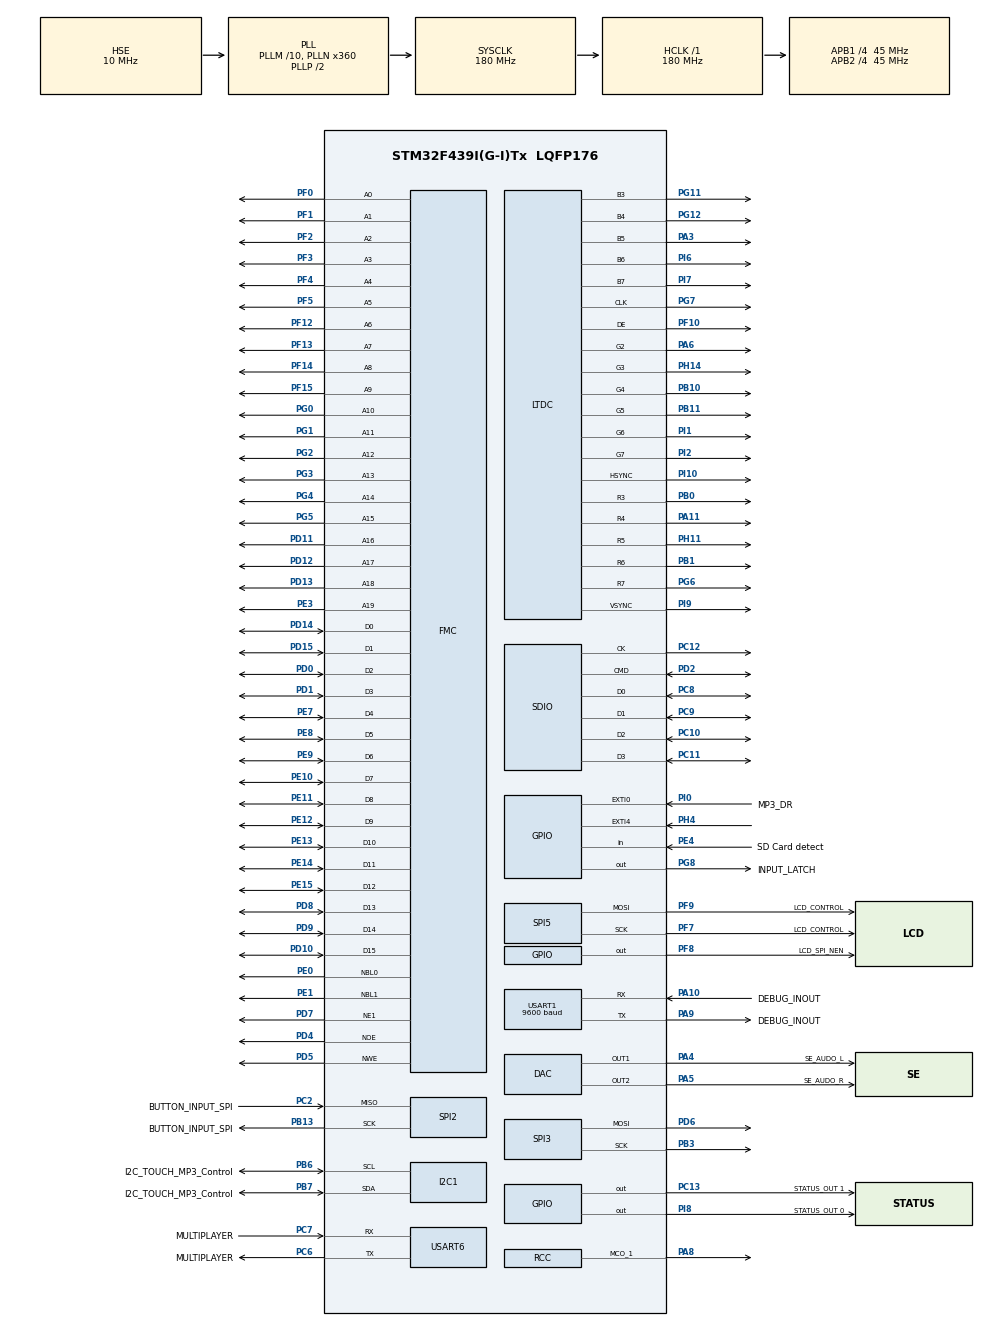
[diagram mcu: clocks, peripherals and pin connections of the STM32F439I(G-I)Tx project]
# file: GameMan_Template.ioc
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FATFS._USE_LFN=3
FATFS._USE_MKFS=1
FMC.AddressSetupTime1=0
FMC.BusTurnAroundDuration1=0
FMC.DataSetupTime1=2
FMC.WriteOperation1=FMC_WRITE_OPERATION_ENABLE
I2C1.NoStretchMode=I2C_NOSTRETCH_DISABLED
LTDC.ActiveH-RGB565=240
LTDC.ActiveW-RGB565=320
LTDC.DEPolarity-RGB565=LTDC_DEPOLARITY_AL
LTDC.HBP-RGB565=70
LTDC.HFP-RGB565=18
LTDC.HSync-RGB565=1
LTDC.VBP-RGB565=13
LTDC.VFP-RGB565=10
LTDC.VSync-RGB565=1
Mcu.Family=STM32F4
Mcu.Name=STM32F439I(G-I)Tx
Mcu.Package=LQFP176
NVIC.PriorityGroup=NVIC_PRIORITYGROUP_4
PA10.GPIO_Label=DEBUG_INOUT
PA10.GPIO_Mode=GPIO_MODE_AF_PP
PA10.GPIO_PuPd=GPIO_PULLUP
PA10.GPIO_Speed=GPIO_SPEED_MEDIUM
PA10.Mode=Asynchronous
PA10.Signal=USART1_RX
PA11.GPIO_Mode=GPIO_MODE_AF_PP
PA11.GPIO_PuPd=GPIO_NOPULL
PA11.GPIO_Speed=GPIO_SPEED_MEDIUM
PA11.Mode=RGB565
PA11.Signal=LTDC_R4
PA13.Mode=Serial-Wire
PA13.Signal=SYS_JTMS-SWDIO
PA14.Mode=Serial-Wire
PA14.Signal=SYS_JTCK-SWCLK
PA3.GPIO_Mode=GPIO_MODE_AF_PP
PA3.GPIO_PuPd=GPIO_NOPULL
PA3.GPIO_Speed=GPIO_SPEED_MEDIUM
PA3.Mode=RGB565
PA3.Signal=LTDC_B5
PA4.GPIO_Label=SE_AUDO_L
PA4.GPIO_Mode=GPIO_MODE_ANALOG
PA4.GPIO_PuPd=GPIO_NOPULL
PA4.Signal=COMP_DAC1_group
PA5.GPIO_Label=SE_AUDO_R
PA5.GPIO_Mode=GPIO_MODE_ANALOG
PA5.GPIO_PuPd=GPIO_NOPULL
PA5.Signal=COMP_DAC2_group
PA6.GPIO_Mode=GPIO_MODE_AF_PP
PA6.GPIO_PuPd=GPIO_NOPULL
PA6.GPIO_Speed=GPIO_SPEED_MEDIUM
PA6.Mode=RGB565
PA6.Signal=LTDC_G2
PA8.Mode=Clock-out-1
PA8.Signal=RCC_MCO_1
PA9.GPIO_Label=DEBUG_INOUT
PA9.GPIO_Mode=GPIO_MODE_AF_PP
PA9.GPIO_PuPd=GPIO_PULLUP
PA9.GPIO_Speed=GPIO_SPEED_MEDIUM
PA9.Mode=Asynchronous
PA9.Signal=USART1_TX
PB0.GPIO_Mode=GPIO_MODE_AF_PP
PB0.GPIO_PuPd=GPIO_NOPULL
PB0.GPIO_Speed=GPIO_SPEED_MEDIUM
PB0.Mode=RGB565
PB0.Signal=LTDC_R3
PB1.GPIO_Mode=GPIO_MODE_AF_PP
PB1.GPIO_PuPd=GPIO_NOPULL
PB1.GPIO_Speed=GPIO_SPEED_MEDIUM
PB1.Mode=RGB565
PB1.Signal=LTDC_R6
PB10.GPIO_Mode=GPIO_MODE_AF_PP
PB10.GPIO_PuPd=GPIO_NOPULL
PB10.GPIO_Speed=GPIO_SPEED_MEDIUM
PB10.Mode=RGB565
PB10.Signal=LTDC_G4
PB11.GPIO_Mode=GPIO_MODE_AF_PP
PB11.GPIO_PuPd=GPIO_NOPULL
PB11.GPIO_Speed=GPIO_SPEED_MEDIUM
PB11.Mode=RGB565
PB11.Signal=LTDC_G5
PB13.GPIO_Label=BUTTON_INPUT_SPI
PB13.GPIO_Mode=GPIO_MODE_AF_PP
PB13.GPIO_PuPd=GPIO_NOPULL
PB13.GPIO_Speed=GPIO_SPEED_FAST
PB13.Mode=RX_Only_Simplex_Unidirect_Master
PB13.Signal=SPI2_SCK
PB3.GPIO_Mode=GPIO_MODE_AF_PP
PB3.GPIO_PuPd=GPIO_NOPULL
PB3.GPIO_Speed=GPIO_SPEED_FAST
PB3.Mode=TX_Only_Simplex_Unidirect_Master
PB3.Signal=SPI3_SCK
PB6.GPIO_Label=I2C_TOUCH_MP3_Control
PB6.GPIO_Mode=GPIO_MODE_AF_OD
PB6.GPIO_PuPdOD=GPIO_PULLUP
PB6.GPIO_Speed=GPIO_SPEED_LOW
PB6.Mode=I2C
PB6.Signal=I2C1_SCL
PB7.GPIO_Label=I2C_TOUCH_MP3_Control
PB7.GPIO_Mode=GPIO_MODE_AF_OD
PB7.GPIO_PuPdOD=GPIO_PULLUP
PB7.GPIO_Speed=GPIO_SPEED_LOW
PB7.Mode=I2C
PB7.Signal=I2C1_SDA
PC10.GPIO_Mode=GPIO_MODE_AF_PP
PC10.GPIO_PuPd=GPIO_NOPULL
PC10.GPIO_Speed=GPIO_SPEED_HIGH
PC10.Mode=SD_4_bits_Wide_bus
PC10.Signal=SDIO_D2
PC11.GPIO_Mode=GPIO_MODE_AF_PP
PC11.GPIO_PuPd=GPIO_NOPULL
PC11.GPIO_Speed=GPIO_SPEED_HIGH
PC11.Mode=SD_4_bits_Wide_bus
PC11.Signal=SDIO_D3
PC12.GPIO_Mode=GPIO_MODE_AF_PP
PC12.GPIO_PuPd=GPIO_NOPULL
PC12.GPIO_Speed=GPIO_SPEED_HIGH
PC12.Mode=SD_4_bits_Wide_bus
PC12.Signal=SDIO_CK
PC13.GPIO_Label=STATUS_OUT 1
PC13.GPIO_ModeDefaultOutputPP=GPIO_MODE_OUTPUT_PP
PC13.GPIO_PuPd=GPIO_NOPULL
PC13.GPIO_Speed=GPIO_SPEED_LOW
PC13.Signal=GPIO_Output
PC14/OSC32_IN.Mode=LSE-External-Oscillator
PC14/OSC32_IN.Signal=RCC_OSC32_IN
PC15/OSC32_OUT.Mode=LSE-External-Oscillator
PC15/OSC32_OUT.Signal=RCC_OSC32_OUT
PC2.GPIO_Label=BUTTON_INPUT_SPI
PC2.GPIO_Mode=GPIO_MODE_AF_PP
PC2.GPIO_PuPd=GPIO_NOPULL
PC2.GPIO_Speed=GPIO_SPEED_FAST
PC2.Mode=RX_Only_Simplex_Unidirect_Master
PC2.Signal=SPI2_MISO
PC6.GPIO_Label=MULTIPLAYER
PC6.GPIO_Mode=GPIO_MODE_AF_PP
PC6.GPIO_PuPd=GPIO_PULLUP
PC6.GPIO_Speed=GPIO_SPEED_LOW
PC6.Mode=Asynchronous
PC6.Signal=USART6_TX
PC7.GPIO_Label=MULTIPLAYER
PC7.GPIO_Mode=GPIO_MODE_AF_PP
PC7.GPIO_PuPd=GPIO_PULLUP
PC7.GPIO_Speed=GPIO_SPEED_LOW
PC7.Mode=Asynchronous
PC7.Signal=USART6_RX
PC8.GPIO_Mode=GPIO_MODE_AF_PP
PC8.GPIO_PuPd=GPIO_NOPULL
PC8.GPIO_Speed=GPIO_SPEED_HIGH
PC8.Mode=SD_4_bits_Wide_bus
PC8.Signal=SDIO_D0
PC9.GPIO_Mode=GPIO_MODE_AF_PP
PC9.GPIO_PuPd=GPIO_NOPULL
PC9.GPIO_Speed=GPIO_SPEED_HIGH
PC9.Mode=SD_4_bits_Wide_bus
PC9.Signal=SDIO_D1
PD0.GPIO_Mode=GPIO_MODE_AF_PP
PD0.GPIO_PuPd=GPIO_NOPULL
PD0.GPIO_Speed=GPIO_SPEED_HIGH
PD0.Signal=FMC_D2_DA2
PD1.GPIO_Mode=GPIO_MODE_AF_PP
PD1.GPIO_PuPd=GPIO_NOPULL
PD1.GPIO_Speed=GPIO_SPEED_HIGH
PD1.Signal=FMC_D3_DA3
PD10.GPIO_Mode=GPIO_MODE_AF_PP
PD10.GPIO_PuPd=GPIO_NOPULL
PD10.GPIO_Speed=GPIO_SPEED_HIGH
PD10.Signal=FMC_D15_DA15
PD11.GPIO_Mode=GPIO_MODE_AF_PP
PD11.GPIO_PuPd=GPIO_NOPULL
PD11.GPIO_Speed=GPIO_SPEED_HIGH
PD11.Signal=FMC_A16_CLE
PD12.GPIO_Mode=GPIO_MODE_AF_PP
PD12.GPIO_PuPd=GPIO_NOPULL
PD12.GPIO_Speed=GPIO_SPEED_HIGH
PD12.Signal=FMC_A17_ALE
PD13.GPIO_Mode=GPIO_MODE_AF_PP
PD13.GPIO_PuPd=GPIO_NOPULL
PD13.GPIO_Speed=GPIO_SPEED_HIGH
PD13.Signal=FMC_A18
PD14.GPIO_Mode=GPIO_MODE_AF_PP
PD14.GPIO_PuPd=GPIO_NOPULL
PD14.GPIO_Speed=GPIO_SPEED_HIGH
PD14.Signal=FMC_D0_DA0
PD15.GPIO_Mode=GPIO_MODE_AF_PP
PD15.GPIO_PuPd=GPIO_NOPULL
PD15.GPIO_Speed=GPIO_SPEED_HIGH
PD15.Signal=FMC_D1_DA1
PD2.GPIO_Mode=GPIO_MODE_AF_PP
PD2.GPIO_PuPd=GPIO_NOPULL
PD2.GPIO_Speed=GPIO_SPEED_HIGH
PD2.Mode=SD_4_bits_Wide_bus
PD2.Signal=SDIO_CMD
PD4.GPIO_Mode=GPIO_MODE_AF_PP
PD4.GPIO_PuPd=GPIO_NOPULL
PD4.GPIO_Speed=GPIO_SPEED_HIGH
PD4.Signal=FMC_NOE
PD5.GPIO_Mode=GPIO_MODE_AF_PP
PD5.GPIO_PuPd=GPIO_NOPULL
PD5.GPIO_Speed=GPIO_SPEED_HIGH
PD5.Signal=FMC_NWE
PD6.GPIO_Mode=GPIO_MODE_AF_PP
PD6.GPIO_PuPd=GPIO_NOPULL
PD6.GPIO_Speed=GPIO_SPEED_FAST
PD6.Mode=TX_Only_Simplex_Unidirect_Master
PD6.Signal=SPI3_MOSI
PD7.GPIO_Mode=GPIO_MODE_AF_PP
PD7.GPIO_PuPd=GPIO_NOPULL
PD7.GPIO_Speed=GPIO_SPEED_HIGH
PD7.Mode=NorPsramChipSelect1_1
PD7.Signal=FMC_NE1
PD8.GPIO_Mode=GPIO_MODE_AF_PP
PD8.GPIO_PuPd=GPIO_NOPULL
PD8.GPIO_Speed=GPIO_SPEED_HIGH
PD8.Signal=FMC_D13_DA13
PD9.GPIO_Mode=GPIO_MODE_AF_PP
PD9.GPIO_PuPd=GPIO_NOPULL
PD9.GPIO_Speed=GPIO_SPEED_HIGH
PD9.Signal=FMC_D14_DA14
PE0.GPIO_Mode=GPIO_MODE_AF_PP
PE0.GPIO_PuPd=GPIO_NOPULL
PE0.GPIO_Speed=GPIO_SPEED_HIGH
PE0.Signal=FMC_NBL0
PE1.GPIO_Mode=GPIO_MODE_AF_PP
PE1.GPIO_PuPd=GPIO_NOPULL
PE1.GPIO_Speed=GPIO_SPEED_HIGH
PE1.Signal=FMC_NBL1
PE10.GPIO_Mode=GPIO_MODE_AF_PP
PE10.GPIO_PuPd=GPIO_NOPULL
PE10.GPIO_Speed=GPIO_SPEED_HIGH
PE10.Signal=FMC_D7_DA7
PE11.GPIO_Mode=GPIO_MODE_AF_PP
PE11.GPIO_PuPd=GPIO_NOPULL
PE11.GPIO_Speed=GPIO_SPEED_HIGH
PE11.Signal=FMC_D8_DA8
PE12.GPIO_Mode=GPIO_MODE_AF_PP
PE12.GPIO_PuPd=GPIO_NOPULL
PE12.GPIO_Speed=GPIO_SPEED_HIGH
PE12.Signal=FMC_D9_DA9
PE13.GPIO_Mode=GPIO_MODE_AF_PP
PE13.GPIO_PuPd=GPIO_NOPULL
PE13.GPIO_Speed=GPIO_SPEED_HIGH
PE13.Signal=FMC_D10_DA10
PE14.GPIO_Mode=GPIO_MODE_AF_PP
PE14.GPIO_PuPd=GPIO_NOPULL
PE14.GPIO_Speed=GPIO_SPEED_HIGH
PE14.Signal=FMC_D11_DA11
PE15.GPIO_Mode=GPIO_MODE_AF_PP
PE15.GPIO_PuPd=GPIO_NOPULL
PE15.GPIO_Speed=GPIO_SPEED_HIGH
PE15.Signal=FMC_D12_DA12
PE3.GPIO_Mode=GPIO_MODE_AF_PP
PE3.GPIO_PuPd=GPIO_NOPULL
PE3.GPIO_Speed=GPIO_SPEED_HIGH
PE3.Signal=FMC_A19
PE4.GPIO_Label=SD Card detect
PE4.GPIO_Mode=GPIO_MODE_INPUT
PE4.GPIO_PuPd=GPIO_NOPULL
PE4.Signal=GPIO_Input
PE7.GPIO_Mode=GPIO_MODE_AF_PP
PE7.GPIO_PuPd=GPIO_NOPULL
PE7.GPIO_Speed=GPIO_SPEED_HIGH
PE7.Signal=FMC_D4_DA4
PE8.GPIO_Mode=GPIO_MODE_AF_PP
PE8.GPIO_PuPd=GPIO_NOPULL
PE8.GPIO_Speed=GPIO_SPEED_HIGH
PE8.Signal=FMC_D5_DA5
PE9.GPIO_Mode=GPIO_MODE_AF_PP
PE9.GPIO_PuPd=GPIO_NOPULL
PE9.GPIO_Speed=GPIO_SPEED_HIGH
PE9.Signal=FMC_D6_DA6
PF0.GPIO_Mode=GPIO_MODE_AF_PP
PF0.GPIO_PuPd=GPIO_NOPULL
PF0.GPIO_Speed=GPIO_SPEED_HIGH
PF0.Signal=FMC_A0
PF1.GPIO_Mode=GPIO_MODE_AF_PP
PF1.GPIO_PuPd=GPIO_NOPULL
PF1.GPIO_Speed=GPIO_SPEED_HIGH
PF1.Signal=FMC_A1
PF10.GPIO_Mode=GPIO_MODE_AF_PP
PF10.GPIO_PuPd=GPIO_NOPULL
PF10.GPIO_Speed=GPIO_SPEED_MEDIUM
PF10.Mode=RGB565
PF10.Signal=LTDC_DE
PF12.GPIO_Mode=GPIO_MODE_AF_PP
PF12.GPIO_PuPd=GPIO_NOPULL
PF12.GPIO_Speed=GPIO_SPEED_HIGH
PF12.Signal=FMC_A6
PF13.GPIO_Mode=GPIO_MODE_AF_PP
PF13.GPIO_PuPd=GPIO_NOPULL
PF13.GPIO_Speed=GPIO_SPEED_HIGH
PF13.Signal=FMC_A7
PF14.GPIO_Mode=GPIO_MODE_AF_PP
PF14.GPIO_PuPd=GPIO_NOPULL
PF14.GPIO_Speed=GPIO_SPEED_HIGH
PF14.Signal=FMC_A8
PF15.GPIO_Mode=GPIO_MODE_AF_PP
PF15.GPIO_PuPd=GPIO_NOPULL
PF15.GPIO_Speed=GPIO_SPEED_HIGH
PF15.Signal=FMC_A9
PF2.GPIO_Mode=GPIO_MODE_AF_PP
PF2.GPIO_PuPd=GPIO_NOPULL
PF2.GPIO_Speed=GPIO_SPEED_HIGH
PF2.Signal=FMC_A2
PF3.GPIO_Mode=GPIO_MODE_AF_PP
PF3.GPIO_PuPd=GPIO_NOPULL
PF3.GPIO_Speed=GPIO_SPEED_HIGH
PF3.Signal=FMC_A3
PF4.GPIO_Mode=GPIO_MODE_AF_PP
PF4.GPIO_PuPd=GPIO_NOPULL
PF4.GPIO_Speed=GPIO_SPEED_HIGH
PF4.Signal=FMC_A4
PF5.GPIO_Mode=GPIO_MODE_AF_PP
PF5.GPIO_PuPd=GPIO_NOPULL
PF5.GPIO_Speed=GPIO_SPEED_HIGH
PF5.Signal=FMC_A5
PF7.GPIO_Label=LCD_CONTROL
PF7.GPIO_Mode=GPIO_MODE_AF_PP
PF7.GPIO_PuPd=GPIO_NOPULL
PF7.GPIO_Speed=GPIO_SPEED_FAST
PF7.Mode=TX_Only_Simplex_Unidirect_Master
PF7.Signal=SPI5_SCK
PF8.GPIO_Label=LCD_SPI_NEN
PF8.GPIO_ModeDefaultOutputPP=GPIO_MODE_OUTPUT_PP
PF8.GPIO_PuPd=GPIO_NOPULL
PF8.GPIO_Speed=GPIO_SPEED_LOW
PF8.Signal=GPIO_Output
PF9.GPIO_Label=LCD_CONTROL
PF9.GPIO_Mode=GPIO_MODE_AF_PP
PF9.GPIO_PuPd=GPIO_NOPULL
PF9.GPIO_Speed=GPIO_SPEED_FAST
PF9.Mode=TX_Only_Simplex_Unidirect_Master
PF9.Signal=SPI5_MOSI
PG0.GPIO_Mode=GPIO_MODE_AF_PP
PG0.GPIO_PuPd=GPIO_NOPULL
PG0.GPIO_Speed=GPIO_SPEED_HIGH
PG0.Signal=FMC_A10
PG1.GPIO_Mode=GPIO_MODE_AF_PP
PG1.GPIO_PuPd=GPIO_NOPULL
PG1.GPIO_Speed=GPIO_SPEED_HIGH
PG1.Signal=FMC_A11
PG11.GPIO_Mode=GPIO_MODE_AF_PP
PG11.GPIO_PuPd=GPIO_NOPULL
PG11.GPIO_Speed=GPIO_SPEED_MEDIUM
PG11.Mode=RGB565
PG11.Signal=LTDC_B3
PG12.GPIO_Mode=GPIO_MODE_AF_PP
PG12.GPIO_PuPd=GPIO_NOPULL
PG12.GPIO_Speed=GPIO_SPEED_MEDIUM
PG12.Mode=RGB565
PG12.Signal=LTDC_B4
PG2.GPIO_Mode=GPIO_MODE_AF_PP
PG2.GPIO_PuPd=GPIO_NOPULL
PG2.GPIO_Speed=GPIO_SPEED_HIGH
PG2.Signal=FMC_A12
PG3.GPIO_Mode=GPIO_MODE_AF_PP
PG3.GPIO_PuPd=GPIO_NOPULL
PG3.GPIO_Speed=GPIO_SPEED_HIGH
PG3.Signal=FMC_A13
PG4.GPIO_Mode=GPIO_MODE_AF_PP
PG4.GPIO_PuPd=GPIO_NOPULL
PG4.GPIO_Speed=GPIO_SPEED_HIGH
PG4.Signal=FMC_A14_BA0
PG5.GPIO_Mode=GPIO_MODE_AF_PP
PG5.GPIO_PuPd=GPIO_NOPULL
PG5.GPIO_Speed=GPIO_SPEED_HIGH
PG5.Signal=FMC_A15_BA1
PG6.GPIO_Mode=GPIO_MODE_AF_PP
PG6.GPIO_PuPd=GPIO_NOPULL
PG6.GPIO_Speed=GPIO_SPEED_MEDIUM
PG6.Mode=RGB565
PG6.Signal=LTDC_R7
PG7.GPIO_Mode=GPIO_MODE_AF_PP
PG7.GPIO_PuPd=GPIO_NOPULL
PG7.GPIO_Speed=GPIO_SPEED_MEDIUM
PG7.Mode=RGB565
PG7.Signal=LTDC_CLK
PG8.GPIO_Label=INPUT_LATCH
PG8.GPIO_ModeDefaultOutputPP=GPIO_MODE_OUTPUT_PP
PG8.GPIO_PuPd=GPIO_NOPULL
PG8.GPIO_Speed=GPIO_SPEED_LOW
PG8.Signal=GPIO_Output
PH0/OSC_IN.Mode=HSE-External-Oscillator
PH0/OSC_IN.Signal=RCC_OSC_IN
PH1/OSC_OUT.Mode=HSE-External-Oscillator
PH1/OSC_OUT.Signal=RCC_OSC_OUT
PH11.GPIO_Mode=GPIO_MODE_AF_PP
PH11.GPIO_PuPd=GPIO_NOPULL
PH11.GPIO_Speed=GPIO_SPEED_MEDIUM
PH11.Mode=RGB565
PH11.Signal=LTDC_R5
PH14.GPIO_Mode=GPIO_MODE_AF_PP
PH14.GPIO_PuPd=GPIO_NOPULL
PH14.GPIO_Speed=GPIO_SPEED_MEDIUM
PH14.Mode=RGB565
PH14.Signal=LTDC_G3
PH4.Signal=GPXTI4
PI0.GPIO_Label=MP3_DR
PI0.GPIO_ModeDefaultEXTI=GPIO_MODE_EVT_RISING
PI0.GPIO_PuPd=GPIO_NOPULL
PI0.Signal=GPXTI0
PI1.GPIO_Mode=GPIO_MODE_AF_PP
PI1.GPIO_PuPd=GPIO_NOPULL
PI1.GPIO_Speed=GPIO_SPEED_MEDIUM
PI1.Mode=RGB565
PI1.Signal=LTDC_G6
PI10.GPIO_Mode=GPIO_MODE_AF_PP
PI10.GPIO_PuPd=GPIO_NOPULL
PI10.GPIO_Speed=GPIO_SPEED_MEDIUM
PI10.Mode=RGB565
PI10.Signal=LTDC_HSYNC
PI2.GPIO_Mode=GPIO_MODE_AF_PP
PI2.GPIO_PuPd=GPIO_NOPULL
PI2.GPIO_Speed=GPIO_SPEED_MEDIUM
PI2.Mode=RGB565
PI2.Signal=LTDC_G7
PI6.GPIO_Mode=GPIO_MODE_AF_PP
PI6.GPIO_PuPd=GPIO_NOPULL
PI6.GPIO_Speed=GPIO_SPEED_MEDIUM
PI6.Mode=RGB565
PI6.Signal=LTDC_B6
PI7.GPIO_Mode=GPIO_MODE_AF_PP
PI7.GPIO_PuPd=GPIO_NOPULL
PI7.GPIO_Speed=GPIO_SPEED_MEDIUM
PI7.Mode=RGB565
PI7.Signal=LTDC_B7
PI8.GPIO_Label=STATUS_OUT 0
PI8.GPIO_ModeDefaultOutputPP=GPIO_MODE_OUTPUT_PP
PI8.GPIO_PuPd=GPIO_NOPULL
PI8.GPIO_Speed=GPIO_SPEED_LOW
PI8.Signal=GPIO_Output
PI9.GPIO_Mode=GPIO_MODE_AF_PP
PI9.GPIO_PuPd=GPIO_NOPULL
PI9.GPIO_Speed=GPIO_SPEED_MEDIUM
PI9.Mode=RGB565
PI9.Signal=LTDC_VSYNC
ProjectManager.TargetToolchain=MDK-ARM 4.73
RCC.48MHZClocksFreq_Value=45000000
RCC.AHBFreq_Value=180000000
RCC.APB1CLKDivider=RCC_HCLK_DIV4
RCC.APB1Freq_Value=45000000
RCC.APB1TimFreq_Value=90000000
RCC.APB2CLKDivider=RCC_HCLK_DIV4
RCC.APB2Freq_Value=45000000
RCC.APB2TimFreq_Value=90000000
RCC.CortexFreq_Value=22500000
RCC.HCLKFreq_Value=180000000
RCC.HSE_VALUE=10000000
RCC.HSI_VALUE=16000000
RCC.LSE_VALUE=32768
RCC.PLLM=10
RCC.PLLN=360
RCC.PLLQ=8
RCC.PLLSAIDivR=RCC_PLLSAIDIVR_8
RCC.PLLSAIN=256
RCC.PLLSAIR=5
RCC.PLLSourceVirtual=RCC_PLLSOURCE_HSE
RCC.SYSCLKFreq_VALUE=180000000
RCC.SYSCLKSource=RCC_SYSCLKSOURCE_PLLCLK
RCC.VCOOutputFreq_Value=360000000
SDIO.BusWide-SD_4_bits_Wide_bus=SDIO_BUS_WIDE_4B
SH.COMP_DAC1_group.0=DAC_OUT1,DAC_OUT1
SH.COMP_DAC2_group.0=DAC_OUT2,DAC_OUT2
SH.FMC_A0.0=FMC_A0,20b-a1
SH.FMC_A1.0=FMC_A1,20b-a1
SH.FMC_A10.0=FMC_A10,20b-a1
SH.FMC_A11.0=FMC_A11,20b-a1
SH.FMC_A12.0=FMC_A12,20b-a1
SH.FMC_A13.0=FMC_A13,20b-a1
SH.FMC_A14_BA0.0=FMC_A14,20b-a1
SH.FMC_A15_BA1.0=FMC_A15,20b-a1
SH.FMC_A16_CLE.0=FMC_A16,20b-a1
SH.FMC_A17_ALE.0=FMC_A17,20b-a1
SH.FMC_A18.0=FMC_A18,20b-a1
SH.FMC_A19.0=FMC_A19,20b-a1
SH.FMC_A2.0=FMC_A2,20b-a1
SH.FMC_A3.0=FMC_A3,20b-a1
SH.FMC_A4.0=FMC_A4,20b-a1
SH.FMC_A5.0=FMC_A5,20b-a1
SH.FMC_A6.0=FMC_A6,20b-a1
SH.FMC_A7.0=FMC_A7,20b-a1
SH.FMC_A8.0=FMC_A8,20b-a1
SH.FMC_A9.0=FMC_A9,20b-a1
SH.FMC_D0_DA0.0=FMC_D0,16b-d1
SH.FMC_D10_DA10.0=FMC_D10,16b-d1
SH.FMC_D11_DA11.0=FMC_D11,16b-d1
SH.FMC_D12_DA12.0=FMC_D12,16b-d1
SH.FMC_D13_DA13.0=FMC_D13,16b-d1
SH.FMC_D14_DA14.0=FMC_D14,16b-d1
SH.FMC_D15_DA15.0=FMC_D15,16b-d1
SH.FMC_D1_DA1.0=FMC_D1,16b-d1
SH.FMC_D2_DA2.0=FMC_D2,16b-d1
SH.FMC_D3_DA3.0=FMC_D3,16b-d1
SH.FMC_D4_DA4.0=FMC_D4,16b-d1
SH.FMC_D5_DA5.0=FMC_D5,16b-d1
SH.FMC_D6_DA6.0=FMC_D6,16b-d1
SH.FMC_D7_DA7.0=FMC_D7,16b-d1
SH.FMC_D8_DA8.0=FMC_D8,16b-d1
SH.FMC_D9_DA9.0=FMC_D9,16b-d1
SH.FMC_NBL0.0=FMC_NBL0,2ByteEnable1
SH.FMC_NBL1.0=FMC_NBL1,2ByteEnable1
SH.FMC_NOE.0=FMC_NOE,Sram1
SH.FMC_NWE.0=FMC_NWE,Sram1
SPI2.CalculateBaudRate-RX_Only_Simplex_Unidirect_Master=22.5 MBits/s
SPI2.DataSize-RX_Only_Simplex_Unidirect_Master=SPI_DATASIZE_16BIT
SPI2.Direction-RX_Only_Simplex_Unidirect_Master=SPI_DIRECTION_2LINES_RXONLY
SPI2.Mode-RX_Only_Simplex_Unidirect_Master=SPI_MODE_MASTER
SPI3.BaudRatePrescaler-TX_Only_Simplex_Unidirect_Master=SPI_BAUDRATEPRESCALER_4
SPI3.CLKPolarity-TX_Only_Simplex_Unidirect_Master=SPI_POLARITY_HIGH
SPI3.CalculateBaudRate-TX_Only_Simplex_Unidirect_Master=11.25 MBits/s
SPI3.Mode-TX_Only_Simplex_Unidirect_Master=SPI_MODE_MASTER
SPI5.BaudRatePrescaler-TX_Only_Simplex_Unidirect_Master=SPI_BAUDRATEPRESCALER_16
SPI5.CalculateBaudRate-TX_Only_Simplex_Unidirect_Master=2.8125 MBits/s
SPI5.Mode-TX_Only_Simplex_Unidirect_Master=SPI_MODE_MASTER
USART1.BaudRate=9600
VP_DMA2D_VS_DMA2D.Mode=DMA2D_Activate
VP_FATFS_VS_SDIO.Mode=SDIO
VP_RNG_VS_RNG.Mode=RNG_Activate

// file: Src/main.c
/**
  ******************************************************************************
  * File Name          : main.c
  * Date               : 02/03/2015 17:16:37
  * Description        : Main program body
  ******************************************************************************
  *
  * COPYRIGHT(c) 2015 STMicroelectronics
  *
  * Redistribution and use in source and binary forms, with or without modification,
  * are permitted provided that the following conditions are met:
  *   1. Redistributions of source code must retain the above copyright notice,
  *      this list of conditions and the following disclaimer.
  *   2. Redistributions in binary form must reproduce the above copyright notice,
  *      this list of conditions and the following disclaimer in the documentation
  *      and/or other materials provided with the distribution.
  *   3. Neither the name of STMicroelectronics nor the names of its contributors
  *      may be used to endorse or promote products derived from this software
  *      without specific prior written permission.
  *
  * THIS SOFTWARE IS PROVIDED BY THE COPYRIGHT HOLDERS AND CONTRIBUTORS "AS IS"
  * AND ANY EXPRESS OR IMPLIED WARRANTIES, INCLUDING, BUT NOT LIMITED TO, THE
  * IMPLIED WARRANTIES OF MERCHANTABILITY AND FITNESS FOR A PARTICULAR PURPOSE ARE
  * DISCLAIMED. IN NO EVENT SHALL THE COPYRIGHT HOLDER OR CONTRIBUTORS BE LIABLE
  * FOR ANY DIRECT, INDIRECT, INCIDENTAL, SPECIAL, EXEMPLARY, OR CONSEQUENTIAL
  * DAMAGES (INCLUDING, BUT NOT LIMITED TO, PROCUREMENT OF SUBSTITUTE GOODS OR
  * SERVICES; LOSS OF USE, DATA, OR PROFITS; OR BUSINESS INTERRUPTION) HOWEVER
  * CAUSED AND ON ANY THEORY OF LIABILITY, WHETHER IN CONTRACT, STRICT LIABILITY,
  * OR TORT (INCLUDING NEGLIGENCE OR OTHERWISE) ARISING IN ANY WAY OUT OF THE USE
  * OF THIS SOFTWARE, EVEN IF ADVISED OF THE POSSIBILITY OF SUCH DAMAGE.
  *
  ******************************************************************************
  */

#include "stm32f4xx_hal.h"
#include "ff.h"
#include "ff_gen_drv.h"
#include "sd_diskio.h" /* defines SD_Driver as external */

/* USER CODE BEGIN Includes */
#include "GameMan_RevA0.h"
#include "TestGame.h"
#include "stdio.h"
#include "stdlib.h"

#include "DrawQueue.h"
//for printf rerouting to UART
#include <rt_misc.h>

/* USER CODE END Includes */

DAC_HandleTypeDef hdac;

DMA2D_HandleTypeDef hdma2d;

I2C_HandleTypeDef hi2c1;

LTDC_HandleTypeDef hltdc;

RNG_HandleTypeDef hrng;

SD_HandleTypeDef hsd;
HAL_SD_CardInfoTypedef SDCardInfo;

SPI_HandleTypeDef input_spi;
SPI_HandleTypeDef mp3_spi;
SPI_HandleTypeDef lcd_spi;

UART_HandleTypeDef huart1;
UART_HandleTypeDef huart6;

SRAM_HandleTypeDef hsram1;

uint8_t retSD;    /* Return value for SD */
char SD_Path[4];  /* SD logical drive path */
FIL file;

void SystemClock_Config(void);
static void MX_GPIO_Init(void);
static void MX_DAC_Init(void);
static void MX_DMA2D_Init(void);
static void MX_FMC_Init(void);
static void MX_I2C1_Init(void);
static void MX_LTDC_Init(void);
static void MX_RNG_Init(void);
static void MX_SDIO_SD_Init(void);
static void MX_SPI2_Init(void);
static void MX_SPI3_Init(void);
static void MX_SPI5_Init(void);
static void MX_USART1_UART_Init(void);
static void MX_USART6_UART_Init(void);

/* USER CODE BEGIN PFP */
void configureMP3(uint16_t addr);

/* USER CODE END PFP */

int main(void)
{

  /* USER CODE BEGIN 1 */
	//Declarations
	FATFS sdcard;

	LTDC_LayerCfgTypeDef layer1;
  /* USER CODE END 1 */

  /* MCU Configuration----------------------------------------------------------*/

  /* Reset of all peripherals, Initializes the Flash interface and the Systick. */
  HAL_Init();

  /* Configure the system clock */
  SystemClock_Config();

  /* Initialize all configured peripherals */
  MX_GPIO_Init();
  MX_DAC_Init();
  MX_DMA2D_Init();
  MX_FMC_Init();
  MX_I2C1_Init();
  MX_LTDC_Init();
  MX_RNG_Init();
  MX_SDIO_SD_Init();
  MX_SPI2_Init();
  MX_SPI3_Init();
  MX_SPI5_Init();
  MX_USART1_UART_Init();
  MX_USART6_UART_Init();

  /* USER CODE BEGIN 2 */
	framebuffer_layer_init(&layer1,SPRITE_LAYER_NUM,framebuffer_1);
	NV3035_init();
  /* USER CODE END 2 */

  /*## FatFS: Link the SD driver ###########################*/
  if(FATFS_LinkDriver(&SD_Driver, SD_Path) != 0) //prepare SD card
	{
		if(f_mount(&sdcard,(TCHAR const*)SD_Path,0) != FR_OK)
		{
			Error_Handler();
		}
		else
		{
			//TODO change to 4 bit mode
			runGame();
		}
	}

}

/** System Clock Configuration
*/
void SystemClock_Config(void)
{

  RCC_OscInitTypeDef RCC_OscInitStruct;
  RCC_ClkInitTypeDef RCC_ClkInitStruct;
  RCC_PeriphCLKInitTypeDef PeriphClkInitStruct;

  __PWR_CLK_ENABLE();

  __HAL_PWR_VOLTAGESCALING_CONFIG(PWR_REGULATOR_VOLTAGE_SCALE1);

  RCC_OscInitStruct.OscillatorType = RCC_OSCILLATORTYPE_HSI|RCC_OSCILLATORTYPE_HSE;
  RCC_OscInitStruct.HSEState = RCC_HSE_ON;
  RCC_OscInitStruct.HSIState = RCC_HSI_ON;
  RCC_OscInitStruct.HSICalibrationValue = 6;
  RCC_OscInitStruct.PLL.PLLState = RCC_PLL_ON;
  RCC_OscInitStruct.PLL.PLLSource = RCC_PLLSOURCE_HSE;
  RCC_OscInitStruct.PLL.PLLM = 10;
  RCC_OscInitStruct.PLL.PLLN = 360;
  RCC_OscInitStruct.PLL.PLLP = RCC_PLLP_DIV2;
  RCC_OscInitStruct.PLL.PLLQ = 8;
  HAL_RCC_OscConfig(&RCC_OscInitStruct);

  HAL_PWREx_ActivateOverDrive();

  RCC_ClkInitStruct.ClockType = RCC_CLOCKTYPE_SYSCLK|RCC_CLOCKTYPE_PCLK1
                              |RCC_CLOCKTYPE_PCLK2;
  RCC_ClkInitStruct.SYSCLKSource = RCC_SYSCLKSOURCE_PLLCLK;
  RCC_ClkInitStruct.AHBCLKDivider = RCC_SYSCLK_DIV1;
  RCC_ClkInitStruct.APB1CLKDivider = RCC_HCLK_DIV4;
  RCC_ClkInitStruct.APB2CLKDivider = RCC_HCLK_DIV4;
  HAL_RCC_ClockConfig(&RCC_ClkInitStruct, FLASH_LATENCY_5);

  PeriphClkInitStruct.PeriphClockSelection = RCC_PERIPHCLK_LTDC;
  PeriphClkInitStruct.PLLSAI.PLLSAIN = 256;
  PeriphClkInitStruct.PLLSAI.PLLSAIR = 5;
  PeriphClkInitStruct.PLLSAIDivR = RCC_PLLSAIDIVR_8;
  HAL_RCCEx_PeriphCLKConfig(&PeriphClkInitStruct);

  HAL_RCC_MCOConfig(RCC_MCO1, RCC_MCO1SOURCE_HSI, RCC_MCODIV_1);

}

/* DAC init function */
void MX_DAC_Init(void)
{

  DAC_ChannelConfTypeDef sConfig;

    /**DAC Initialization
    */
  hdac.Instance = DAC;
  HAL_DAC_Init(&hdac);

    /**DAC channel OUT1 config
    */
  sConfig.DAC_Trigger = DAC_TRIGGER_NONE;
  sConfig.DAC_OutputBuffer = DAC_OUTPUTBUFFER_ENABLE;
  HAL_DAC_ConfigChannel(&hdac, &sConfig, DAC_CHANNEL_1);

    /**DAC channel OUT2 config
    */
  HAL_DAC_ConfigChannel(&hdac, &sConfig, DAC_CHANNEL_2);

}

/* DMA2D init function */
void MX_DMA2D_Init(void)
{

  hdma2d.Instance = DMA2D;
  hdma2d.Init.Mode = DMA2D_M2M;
  hdma2d.Init.ColorMode = DMA2D_ARGB8888;
  hdma2d.Init.OutputOffset = 0;
  HAL_DMA2D_Init(&hdma2d);

}

/* I2C1 init function */
void MX_I2C1_Init(void)
{

  hi2c1.Instance = I2C1;
  hi2c1.Init.ClockSpeed = 100000;
  hi2c1.Init.DutyCycle = I2C_DUTYCYCLE_2;
  hi2c1.Init.OwnAddress1 = 0;
  hi2c1.Init.AddressingMode = I2C_ADDRESSINGMODE_7BIT;
  hi2c1.Init.DualAddressMode = I2C_DUALADDRESS_DISABLED;
  hi2c1.Init.OwnAddress2 = 0;
  hi2c1.Init.GeneralCallMode = I2C_GENERALCALL_DISABLED;
  hi2c1.Init.NoStretchMode = I2C_NOSTRETCH_DISABLED;
  HAL_I2C_Init(&hi2c1);

}

/* LTDC init function */
void MX_LTDC_Init(void)
{
  hltdc.Instance = LTDC;
  hltdc.Init.HSPolarity = LTDC_HSPOLARITY_AL;
  hltdc.Init.VSPolarity = LTDC_VSPOLARITY_AL;
  hltdc.Init.DEPolarity = LTDC_DEPOLARITY_AL;
  hltdc.Init.PCPolarity = LTDC_PCPOLARITY_IPC;
  hltdc.Init.HorizontalSync = 0;
  hltdc.Init.VerticalSync = 0;
  hltdc.Init.AccumulatedHBP = 70;
  hltdc.Init.AccumulatedVBP = 13;
  hltdc.Init.AccumulatedActiveW = 390;
  hltdc.Init.AccumulatedActiveH = 253;
  hltdc.Init.TotalWidth = 408;
  hltdc.Init.TotalHeigh = 263;
  hltdc.Init.Backcolor.Blue = 0;
  hltdc.Init.Backcolor.Green = 0;
  hltdc.Init.Backcolor.Red = 0;
  HAL_LTDC_Init(&hltdc);

}

/* RNG init function */
void MX_RNG_Init(void)
{

  hrng.Instance = RNG;
  HAL_RNG_Init(&hrng);

}

/* SDIO init function */
void MX_SDIO_SD_Init(void)
{

  hsd.Instance = SDIO;
  hsd.Init.ClockEdge = SDIO_CLOCK_EDGE_RISING;
  hsd.Init.ClockBypass = SDIO_CLOCK_BYPASS_DISABLE;
  hsd.Init.ClockPowerSave = SDIO_CLOCK_POWER_SAVE_DISABLE;
  hsd.Init.BusWide = SDIO_BUS_WIDE_1B;
  hsd.Init.HardwareFlowControl = SDIO_HARDWARE_FLOW_CONTROL_DISABLE;
  hsd.Init.ClockDiv = 0;

}

/* SPI2 init function */
void MX_SPI2_Init(void)
{

  input_spi.Instance = SPI2;
  input_spi.Init.Mode = SPI_MODE_MASTER;
  input_spi.Init.Direction = SPI_DIRECTION_2LINES;
  input_spi.Init.DataSize = SPI_DATASIZE_16BIT;
  input_spi.Init.CLKPolarity = SPI_POLARITY_LOW;
  input_spi.Init.CLKPhase = SPI_PHASE_1EDGE;
  input_spi.Init.NSS = SPI_NSS_SOFT;
  input_spi.Init.BaudRatePrescaler = SPI_BAUDRATEPRESCALER_2;
  input_spi.Init.FirstBit = SPI_FIRSTBIT_MSB;
  input_spi.Init.TIMode = SPI_TIMODE_DISABLED;
  input_spi.Init.CRCCalculation = SPI_CRCCALCULATION_DISABLED;
  HAL_SPI_Init(&input_spi);

}

/* SPI3 init function */
void MX_SPI3_Init(void)
{

  mp3_spi.Instance = SPI3;
  mp3_spi.Init.Mode = SPI_MODE_MASTER;
  mp3_spi.Init.Direction = SPI_DIRECTION_2LINES;
  mp3_spi.Init.DataSize = SPI_DATASIZE_8BIT;
  mp3_spi.Init.CLKPolarity = SPI_POLARITY_HIGH;
  mp3_spi.Init.CLKPhase = SPI_PHASE_1EDGE;
  mp3_spi.Init.NSS = SPI_NSS_SOFT;
  mp3_spi.Init.BaudRatePrescaler = SPI_BAUDRATEPRESCALER_4;
  mp3_spi.Init.FirstBit = SPI_FIRSTBIT_MSB;
  mp3_spi.Init.TIMode = SPI_TIMODE_DISABLED;
  mp3_spi.Init.CRCCalculation = SPI_CRCCALCULATION_DISABLED;
  HAL_SPI_Init(&mp3_spi);

}

/* SPI5 init function */
void MX_SPI5_Init(void)
{

  lcd_spi.Instance = SPI5;
  lcd_spi.Init.Mode = SPI_MODE_MASTER;
  lcd_spi.Init.Direction = SPI_DIRECTION_2LINES;
  lcd_spi.Init.DataSize = SPI_DATASIZE_8BIT;
  lcd_spi.Init.CLKPolarity = SPI_POLARITY_LOW;
  lcd_spi.Init.CLKPhase = SPI_PHASE_1EDGE;
  lcd_spi.Init.NSS = SPI_NSS_SOFT;
  lcd_spi.Init.BaudRatePrescaler = SPI_BAUDRATEPRESCALER_16;
  lcd_spi.Init.FirstBit = SPI_FIRSTBIT_MSB;
  lcd_spi.Init.TIMode = SPI_TIMODE_DISABLED;
  lcd_spi.Init.CRCCalculation = SPI_CRCCALCULATION_DISABLED;
  HAL_SPI_Init(&lcd_spi);

}

/* USART1 init function */
void MX_USART1_UART_Init(void)
{

  huart1.Instance = USART1;
  huart1.Init.BaudRate = 9600;
  huart1.Init.WordLength = UART_WORDLENGTH_8B;
  huart1.Init.StopBits = UART_STOPBITS_1;
  huart1.Init.Parity = UART_PARITY_NONE;
  huart1.Init.Mode = UART_MODE_TX_RX;
  huart1.Init.HwFlowCtl = UART_HWCONTROL_NONE;
  huart1.Init.OverSampling = UART_OVERSAMPLING_16;
  HAL_UART_Init(&huart1);

}

/* USART6 init function */
void MX_USART6_UART_Init(void)
{

  huart6.Instance = USART6;
  huart6.Init.BaudRate = 115200;
  huart6.Init.WordLength = UART_WORDLENGTH_8B;
  huart6.Init.StopBits = UART_STOPBITS_1;
  huart6.Init.Parity = UART_PARITY_NONE;
  huart6.Init.Mode = UART_MODE_TX_RX;
  huart6.Init.HwFlowCtl = UART_HWCONTROL_NONE;
  huart6.Init.OverSampling = UART_OVERSAMPLING_16;
  HAL_UART_Init(&huart6);

}
/* FMC initialization function */
void MX_FMC_Init(void)
{
  FMC_NORSRAM_TimingTypeDef Timing;

  /** Perform the SRAM1 memory initialization sequence
  */
  hsram1.Instance = FMC_NORSRAM_DEVICE;
  hsram1.Extended = FMC_NORSRAM_EXTENDED_DEVICE;
  /* hsram1.Init */
  hsram1.Init.NSBank = FMC_NORSRAM_BANK1;
  hsram1.Init.DataAddressMux = FMC_DATA_ADDRESS_MUX_DISABLE;
  hsram1.Init.MemoryType = FMC_MEMORY_TYPE_SRAM;
  hsram1.Init.MemoryDataWidth = FMC_NORSRAM_MEM_BUS_WIDTH_16;
  hsram1.Init.BurstAccessMode = FMC_BURST_ACCESS_MODE_DISABLE;
  hsram1.Init.WaitSignalPolarity = FMC_WAIT_SIGNAL_POLARITY_LOW;
  hsram1.Init.WrapMode = FMC_WRAP_MODE_DISABLE;
  hsram1.Init.WaitSignalActive = FMC_WAIT_TIMING_BEFORE_WS;
  hsram1.Init.WriteOperation = FMC_WRITE_OPERATION_ENABLE;
  hsram1.Init.WaitSignal = FMC_WAIT_SIGNAL_DISABLE;
  hsram1.Init.ExtendedMode = FMC_EXTENDED_MODE_DISABLE;
  hsram1.Init.AsynchronousWait = FMC_ASYNCHRONOUS_WAIT_DISABLE;
  hsram1.Init.WriteBurst = FMC_WRITE_BURST_DISABLE;
  hsram1.Init.ContinuousClock = FMC_CONTINUOUS_CLOCK_SYNC_ONLY;
  /* Timing */
  Timing.AddressSetupTime = 0;
  Timing.AddressHoldTime = 15;
  Timing.DataSetupTime = 6;
  Timing.BusTurnAroundDuration = 0;
  Timing.CLKDivision = 16;
  Timing.DataLatency = 17;
  Timing.AccessMode = FMC_ACCESS_MODE_A;
  /* ExtTiming */

  HAL_SRAM_Init(&hsram1, &Timing, NULL);

}

/** Configure pins as
        * Analog
        * Input
        * Output
        * EVENT_OUT
        * EXTI
     PA8   ------> RCC_MCO_1
*/
void MX_GPIO_Init(void)
{

  GPIO_InitTypeDef GPIO_InitStruct;

  /* GPIO Ports Clock Enable */
  __GPIOE_CLK_ENABLE();
  __GPIOI_CLK_ENABLE();
  __GPIOC_CLK_ENABLE();
  __GPIOF_CLK_ENABLE();
  __GPIOH_CLK_ENABLE();
  __GPIOA_CLK_ENABLE();
  __GPIOB_CLK_ENABLE();
  __GPIOG_CLK_ENABLE();
  __GPIOD_CLK_ENABLE();

  /*Configure GPIO pin : PE4 */
  GPIO_InitStruct.Pin = GPIO_PIN_4;
  GPIO_InitStruct.Mode = GPIO_MODE_INPUT;
  GPIO_InitStruct.Pull = GPIO_NOPULL;
  HAL_GPIO_Init(GPIOE, &GPIO_InitStruct);

  /*Configure GPIO pin : PI8 */
  GPIO_InitStruct.Pin = GPIO_PIN_8;
  GPIO_InitStruct.Mode = GPIO_MODE_OUTPUT_PP;
  GPIO_InitStruct.Pull = GPIO_NOPULL;
  GPIO_InitStruct.Speed = GPIO_SPEED_LOW;
  HAL_GPIO_Init(GPIOI, &GPIO_InitStruct);

  /*Configure GPIO pin : PC13 */
  GPIO_InitStruct.Pin = GPIO_PIN_13;
  GPIO_InitStruct.Mode = GPIO_MODE_OUTPUT_PP;
  GPIO_InitStruct.Pull = GPIO_NOPULL;
  GPIO_InitStruct.Speed = GPIO_SPEED_LOW;
  HAL_GPIO_Init(GPIOC, &GPIO_InitStruct);

  /*Configure GPIO pin : PF8 */
  GPIO_InitStruct.Pin = GPIO_PIN_8;
  GPIO_InitStruct.Mode = GPIO_MODE_OUTPUT_PP;
  GPIO_InitStruct.Pull = GPIO_NOPULL;
  GPIO_InitStruct.Speed = GPIO_SPEED_LOW;
  HAL_GPIO_Init(GPIOF, &GPIO_InitStruct);

	HAL_GPIO_WritePin(GPIOF,GPIO_PIN_8,GPIO_PIN_SET);

  /*Configure GPIO pin : PH4 */
  GPIO_InitStruct.Pin = GPIO_PIN_4;
  GPIO_InitStruct.Mode = GPIO_MODE_INPUT;
  GPIO_InitStruct.Pull = GPIO_NOPULL;
  HAL_GPIO_Init(GPIOH, &GPIO_InitStruct);

  /*Configure GPIO pin : PG8 */
  GPIO_InitStruct.Pin = GPIO_PIN_8;
  GPIO_InitStruct.Mode = GPIO_MODE_OUTPUT_PP;
  GPIO_InitStruct.Pull = GPIO_NOPULL;
  GPIO_InitStruct.Speed = GPIO_SPEED_HIGH;
  HAL_GPIO_Init(GPIOG, &GPIO_InitStruct);

  /*Configure GPIO pin : PA8 */
  GPIO_InitStruct.Pin = GPIO_PIN_8;
  GPIO_InitStruct.Mode = GPIO_MODE_AF_PP;
  GPIO_InitStruct.Pull = GPIO_NOPULL;
  GPIO_InitStruct.Speed = GPIO_SPEED_LOW;
  GPIO_InitStruct.Alternate = GPIO_AF0_MCO;
  HAL_GPIO_Init(GPIOA, &GPIO_InitStruct);

  /*Configure GPIO pin : PI0 */
  GPIO_InitStruct.Pin = GPIO_PIN_0;
  GPIO_InitStruct.Mode = GPIO_MODE_EVT_RISING;
  GPIO_InitStruct.Pull = GPIO_NOPULL;
  HAL_GPIO_Init(GPIOI, &GPIO_InitStruct);

}

/* USER CODE BEGIN 4 */
//crap not printf debug
HAL_StatusTypeDef print_debug(uint8_t *pData, uint16_t Size, uint32_t Timeout)
{
	return HAL_UART_Transmit(DEBUG_UART,pData,Size, Timeout);
}

//printf configuration from forums
#pragma import(__use_no_semihosting_swi)

struct __FILE { int handle; /* Add whatever you need here */ };
FILE __stdout;
FILE __stdin;

int fputc(int ch, FILE *f)
{
    //while(__HAL_UART_GET_FLAG(DEBUG_UART, UART_FLAG_TXE) == RESET);

  HAL_UART_Transmit(DEBUG_UART, (uint8_t*) &ch, 1, 1000);

  return(ch);
}

int fgetc(FILE *f)
{
    char ch;

    //while(__HAL_UART_GET_FLAG(DEBUG_UART, UART_FLAG_RXNE) == RESET);

    ch = HAL_UART_Receive(DEBUG_UART,(uint8_t*) &ch, 1 , 10);

  return((int)ch);
}

int ferror(FILE *f)
{
  /* Your implementation of ferror */
  return EOF;
}

void _ttywrch(int ch)
{
    //while(HAL_UART_GetFlagStatus(DEBUG_UART, UART_FLAG_TXE) == RESET);

  HAL_UART_Transmit(DEBUG_UART,(uint8_t*) ch, 1, 10);
}

void _sys_exit(int return_code)
{
label:  goto label;  /* endless loop */
}
/* USER CODE END 4 */

/************************ (C) COPYRIGHT STMicroelectronics *****END OF FILE****/
